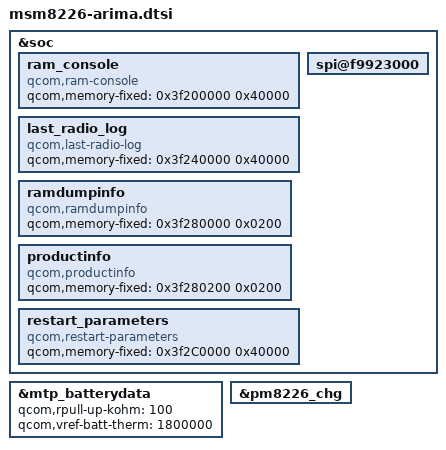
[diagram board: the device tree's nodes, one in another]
/* Copyright (c) 2013-2015, The Linux Foundation. All rights reserved.
 *
 * This program is free software; you can redistribute it and/or modify
 * it under the terms of the GNU General Public License version 2 and
 * only version 2 as published by the Free Software Foundation.
 *
 * This program is distributed in the hope that it will be useful,
 * but WITHOUT ANY WARRANTY; without even the implied warranty of
 * MERCHANTABILITY or FITNESS FOR A PARTICULAR PURPOSE.  See the
 * GNU General Public License for more details.
 */

#include "msm8226-720p-mtp.dtsi"

&soc {
	/* ARIMA ODM ramdump layout expected by userspace/SBL tooling. */
	ram_console {
		compatible = "qcom,ram-console";
		qcom,memory-fixed = <0x3f200000 0x40000>;
	};

	last_radio_log {
		compatible = "qcom,last-radio-log";
		qcom,memory-fixed = <0x3f240000 0x40000>;
	};

	ramdumpinfo {
		compatible = "qcom,ramdumpinfo";
		qcom,memory-fixed = <0x3f280000 0x0200>;
	};

	productinfo {
		compatible = "qcom,productinfo";
		qcom,memory-fixed = <0x3f280200 0x0200>;
	};

	restart_parameters {
		compatible = "qcom,restart-parameters";
		qcom,memory-fixed = <0x3f2C0000 0x40000>;
	};

	/* ARIMA ODM does not use KS8851 ethernet-switch wiring. */
	spi@f9923000 {
		/delete-node/ ethernet-switch@3;
	};
};

&mtp_batterydata {
	qcom,rpull-up-kohm = <100>;
	qcom,vref-batt-therm = <1800000>;
	/delete-node/ qcom,palladium-batterydata;
	/delete-node/ qcom,mtp-3000mah;
	/include/ "batterydata-arima-lucisus2-1458334.dtsi"
};

&pm8226_chg {
	/delete-property/ qcom,charging-disabled;
};
